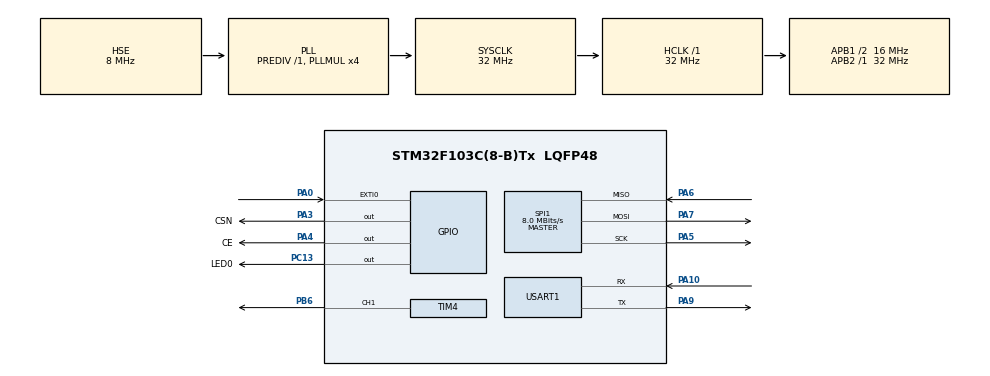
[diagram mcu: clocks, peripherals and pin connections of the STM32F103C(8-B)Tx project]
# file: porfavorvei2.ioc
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Mcu.Family=STM32F1
Mcu.Name=STM32F103C(8-B)Tx
Mcu.Package=LQFP48
NVIC.PriorityGroup=NVIC_PRIORITYGROUP_4
NVIC.SPI1_IRQn=true\:0\:0\:false\:false\:true\:true\:true\:true
NVIC.USART1_IRQn=true\:0\:0\:false\:false\:true\:true\:true\:true
PA0-WKUP.Signal=GPXTI0
PA10.Mode=Asynchronous
PA10.Signal=USART1_RX
PA13.Mode=Serial_Wire
PA13.Signal=SYS_JTMS-SWDIO
PA14.Mode=Serial_Wire
PA14.Signal=SYS_JTCK-SWCLK
PA3.GPIO_Label=CSN
PA3.GPIO_Speed=GPIO_SPEED_FREQ_HIGH
PA3.Signal=GPIO_Output
PA4.GPIO_Label=CE
PA4.GPIO_Speed=GPIO_SPEED_FREQ_HIGH
PA4.Signal=GPIO_Output
PA5.Mode=Full_Duplex_Master
PA5.Signal=SPI1_SCK
PA6.Mode=Full_Duplex_Master
PA6.Signal=SPI1_MISO
PA7.Mode=Full_Duplex_Master
PA7.Signal=SPI1_MOSI
PA9.Mode=Asynchronous
PA9.Signal=USART1_TX
PB6.GPIO_ModeDefaultPP=GPIO_MODE_AF_OD
PB6.Signal=S_TIM4_CH1
PC13-TAMPER-RTC.GPIO_Label=LED0
PC13-TAMPER-RTC.PinState=GPIO_PIN_SET
PC13-TAMPER-RTC.Signal=GPIO_Output
PD0-OSC_IN.Mode=HSE-External-Oscillator
PD0-OSC_IN.Signal=RCC_OSC_IN
PD1-OSC_OUT.Mode=HSE-External-Oscillator
PD1-OSC_OUT.Signal=RCC_OSC_OUT
ProjectManager.HeapSize=0x200
ProjectManager.StackSize=0x400
ProjectManager.TargetToolchain=STM32CubeIDE
RCC.ADCPresc=RCC_ADCPCLK2_DIV6
RCC.AHBFreq_Value=32000000
RCC.APB1CLKDivider=RCC_HCLK_DIV2
RCC.APB1Freq_Value=16000000
RCC.APB1TimFreq_Value=32000000
RCC.APB2Freq_Value=32000000
RCC.APB2TimFreq_Value=32000000
RCC.HCLKFreq_Value=32000000
RCC.PLLMUL=RCC_PLL_MUL4
RCC.PLLSourceVirtual=RCC_PLLSOURCE_HSE
RCC.SYSCLKFreq_VALUE=32000000
RCC.SYSCLKSource=RCC_SYSCLKSOURCE_PLLCLK
RCC.USBFreq_Value=32000000
SH.S_TIM4_CH1.0=TIM4_CH1,PWM Generation1 CH1
SPI1.BaudRatePrescaler=SPI_BAUDRATEPRESCALER_4
SPI1.CalculateBaudRate=8.0 MBits/s
SPI1.Direction=SPI_DIRECTION_2LINES
SPI1.Mode=SPI_MODE_MASTER
SPI1.VirtualType=VM_MASTER
TIM4.Channel-PWM\ Generation1\ CH1=TIM_CHANNEL_1
TIM4.Period=10000
TIM4.Prescaler=144-1
USART1.VirtualMode=VM_ASYNC
VP_TIM4_VS_ClockSourceINT.Mode=Internal
board=custom

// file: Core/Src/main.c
/* USER CODE BEGIN Header */
/**
  ******************************************************************************
  * @file           : main.c
  * @brief          : Main program body
  ******************************************************************************
  * @attention
  *
  * Copyright (c) 2024 STMicroelectronics.
  * All rights reserved.
  *
  * This software is licensed under terms that can be found in the LICENSE file
  * in the root directory of this software component.
  * If no LICENSE file comes with this software, it is provided AS-IS.
  *
  ******************************************************************************
  */
/* USER CODE END Header */
#include "main.h"

/* USER CODE BEGIN Includes */
#include "maincpp.h"

/* USER CODE END Includes */

SPI_HandleTypeDef hspi1;

TIM_HandleTypeDef htim4;

UART_HandleTypeDef huart1;

void SystemClock_Config(void);
static void MX_GPIO_Init(void);
static void MX_TIM4_Init(void);
static void MX_SPI1_Init(void);
static void MX_USART1_UART_Init(void);

int main(void)
{

  /* MCU Configuration--------------------------------------------------------*/

  /* Reset of all peripherals, Initializes the Flash interface and the Systick. */
  HAL_Init();

  /* Configure the system clock */
  SystemClock_Config();

  /* Initialize all configured peripherals */
  MX_GPIO_Init();
  MX_TIM4_Init();
  MX_SPI1_Init();
  MX_USART1_UART_Init();
  /* USER CODE BEGIN 2 */

  maincpp(hspi1, htim4, huart1);
  /* USER CODE END 2 */

  /* Infinite loop */
  while (1)
  {

  }
}

void SystemClock_Config(void)
{
  RCC_OscInitTypeDef RCC_OscInitStruct = {0};
  RCC_ClkInitTypeDef RCC_ClkInitStruct = {0};

  /** Initializes the RCC Oscillators according to the specified parameters
  * in the RCC_OscInitTypeDef structure.
  */
  RCC_OscInitStruct.OscillatorType = RCC_OSCILLATORTYPE_HSE;
  RCC_OscInitStruct.HSEState = RCC_HSE_ON;
  RCC_OscInitStruct.HSEPredivValue = RCC_HSE_PREDIV_DIV1;
  RCC_OscInitStruct.HSIState = RCC_HSI_ON;
  RCC_OscInitStruct.PLL.PLLState = RCC_PLL_ON;
  RCC_OscInitStruct.PLL.PLLSource = RCC_PLLSOURCE_HSE;
  RCC_OscInitStruct.PLL.PLLMUL = RCC_PLL_MUL4;
  if (HAL_RCC_OscConfig(&RCC_OscInitStruct) != HAL_OK)
  {
    Error_Handler();
  }

  /** Initializes the CPU, AHB and APB buses clocks
  */
  RCC_ClkInitStruct.ClockType = RCC_CLOCKTYPE_HCLK|RCC_CLOCKTYPE_SYSCLK
                              |RCC_CLOCKTYPE_PCLK1|RCC_CLOCKTYPE_PCLK2;
  RCC_ClkInitStruct.SYSCLKSource = RCC_SYSCLKSOURCE_PLLCLK;
  RCC_ClkInitStruct.AHBCLKDivider = RCC_SYSCLK_DIV1;
  RCC_ClkInitStruct.APB1CLKDivider = RCC_HCLK_DIV2;
  RCC_ClkInitStruct.APB2CLKDivider = RCC_HCLK_DIV1;

  if (HAL_RCC_ClockConfig(&RCC_ClkInitStruct, FLASH_LATENCY_1) != HAL_OK)
  {
    Error_Handler();
  }
}

static void MX_SPI1_Init(void)
{

  /* SPI1 parameter configuration*/
  hspi1.Instance = SPI1;
  hspi1.Init.Mode = SPI_MODE_MASTER;
  hspi1.Init.Direction = SPI_DIRECTION_2LINES;
  hspi1.Init.DataSize = SPI_DATASIZE_8BIT;
  hspi1.Init.CLKPolarity = SPI_POLARITY_LOW;
  hspi1.Init.CLKPhase = SPI_PHASE_1EDGE;
  hspi1.Init.NSS = SPI_NSS_SOFT;
  hspi1.Init.BaudRatePrescaler = SPI_BAUDRATEPRESCALER_4;
  hspi1.Init.FirstBit = SPI_FIRSTBIT_MSB;
  hspi1.Init.TIMode = SPI_TIMODE_DISABLE;
  hspi1.Init.CRCCalculation = SPI_CRCCALCULATION_DISABLE;
  hspi1.Init.CRCPolynomial = 10;
  if (HAL_SPI_Init(&hspi1) != HAL_OK)
  {
    Error_Handler();
  }

}

static void MX_TIM4_Init(void)
{

  TIM_ClockConfigTypeDef sClockSourceConfig = {0};
  TIM_MasterConfigTypeDef sMasterConfig = {0};
  TIM_OC_InitTypeDef sConfigOC = {0};

  htim4.Instance = TIM4;
  htim4.Init.Prescaler = 144-1;
  htim4.Init.CounterMode = TIM_COUNTERMODE_UP;
  htim4.Init.Period = 10000;
  htim4.Init.ClockDivision = TIM_CLOCKDIVISION_DIV1;
  htim4.Init.AutoReloadPreload = TIM_AUTORELOAD_PRELOAD_DISABLE;
  if (HAL_TIM_Base_Init(&htim4) != HAL_OK)
  {
    Error_Handler();
  }
  sClockSourceConfig.ClockSource = TIM_CLOCKSOURCE_INTERNAL;
  if (HAL_TIM_ConfigClockSource(&htim4, &sClockSourceConfig) != HAL_OK)
  {
    Error_Handler();
  }
  if (HAL_TIM_PWM_Init(&htim4) != HAL_OK)
  {
    Error_Handler();
  }
  sMasterConfig.MasterOutputTrigger = TIM_TRGO_RESET;
  sMasterConfig.MasterSlaveMode = TIM_MASTERSLAVEMODE_DISABLE;
  if (HAL_TIMEx_MasterConfigSynchronization(&htim4, &sMasterConfig) != HAL_OK)
  {
    Error_Handler();
  }
  sConfigOC.OCMode = TIM_OCMODE_PWM1;
  sConfigOC.Pulse = 0;
  sConfigOC.OCPolarity = TIM_OCPOLARITY_HIGH;
  sConfigOC.OCFastMode = TIM_OCFAST_DISABLE;
  if (HAL_TIM_PWM_ConfigChannel(&htim4, &sConfigOC, TIM_CHANNEL_1) != HAL_OK)
  {
    Error_Handler();
  }
  HAL_TIM_MspPostInit(&htim4);

}

static void MX_USART1_UART_Init(void)
{

  huart1.Instance = USART1;
  huart1.Init.BaudRate = 115200;
  huart1.Init.WordLength = UART_WORDLENGTH_8B;
  huart1.Init.StopBits = UART_STOPBITS_1;
  huart1.Init.Parity = UART_PARITY_NONE;
  huart1.Init.Mode = UART_MODE_TX_RX;
  huart1.Init.HwFlowCtl = UART_HWCONTROL_NONE;
  huart1.Init.OverSampling = UART_OVERSAMPLING_16;
  if (HAL_UART_Init(&huart1) != HAL_OK)
  {
    Error_Handler();
  }

}

static void MX_GPIO_Init(void)
{
  GPIO_InitTypeDef GPIO_InitStruct = {0};

  /* GPIO Ports Clock Enable */
  __HAL_RCC_GPIOC_CLK_ENABLE();
  __HAL_RCC_GPIOD_CLK_ENABLE();
  __HAL_RCC_GPIOA_CLK_ENABLE();
  __HAL_RCC_GPIOB_CLK_ENABLE();

  /*Configure GPIO pin Output Level */
  HAL_GPIO_WritePin(LED0_GPIO_Port, LED0_Pin, GPIO_PIN_SET);

  /*Configure GPIO pin Output Level */
  HAL_GPIO_WritePin(GPIOA, CSN_Pin|CE_Pin, GPIO_PIN_RESET);

  /*Configure GPIO pin : LED0_Pin */
  GPIO_InitStruct.Pin = LED0_Pin;
  GPIO_InitStruct.Mode = GPIO_MODE_OUTPUT_PP;
  GPIO_InitStruct.Pull = GPIO_NOPULL;
  GPIO_InitStruct.Speed = GPIO_SPEED_FREQ_LOW;
  HAL_GPIO_Init(LED0_GPIO_Port, &GPIO_InitStruct);

  /*Configure GPIO pin : PA0 */
  GPIO_InitStruct.Pin = GPIO_PIN_0;
  GPIO_InitStruct.Mode = GPIO_MODE_IT_RISING;
  GPIO_InitStruct.Pull = GPIO_NOPULL;
  HAL_GPIO_Init(GPIOA, &GPIO_InitStruct);

  /*Configure GPIO pins : CSN_Pin CE_Pin */
  GPIO_InitStruct.Pin = CSN_Pin|CE_Pin;
  GPIO_InitStruct.Mode = GPIO_MODE_OUTPUT_PP;
  GPIO_InitStruct.Pull = GPIO_NOPULL;
  GPIO_InitStruct.Speed = GPIO_SPEED_FREQ_HIGH;
  HAL_GPIO_Init(GPIOA, &GPIO_InitStruct);

}

void Error_Handler(void)
{
  __disable_irq();
  while (1)
  {
  }
}
